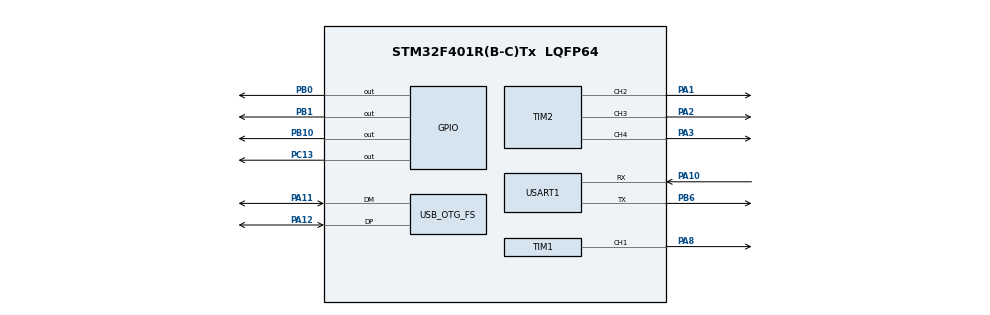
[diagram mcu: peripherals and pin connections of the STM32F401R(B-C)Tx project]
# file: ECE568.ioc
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Mcu.Family=STM32F4
Mcu.Name=STM32F401R(B-C)Tx
Mcu.Package=LQFP64
NVIC.OTG_FS_IRQn=true\:0\:0\:false\:false\:true\:false\:true\:true
NVIC.PriorityGroup=NVIC_PRIORITYGROUP_4
PA1.Signal=S_TIM2_CH2
PA10.Mode=Asynchronous
PA10.Signal=USART1_RX
PA11.Mode=Device_Only
PA11.Signal=USB_OTG_FS_DM
PA12.Mode=Device_Only
PA12.Signal=USB_OTG_FS_DP
PA2.Signal=S_TIM2_CH3
PA3.Signal=S_TIM2_CH4
PA8.Signal=S_TIM1_CH1
PB0.Signal=GPIO_Output
PB1.Signal=GPIO_Output
PB10.Signal=GPIO_Output
PB6.Mode=Asynchronous
PB6.Signal=USART1_TX
PC13-ANTI_TAMP.Signal=GPIO_Output
PH0\ -\ OSC_IN.Mode=HSE-External-Oscillator
PH0\ -\ OSC_IN.Signal=RCC_OSC_IN
PH1\ -\ OSC_OUT.Mode=HSE-External-Oscillator
PH1\ -\ OSC_OUT.Signal=RCC_OSC_OUT
ProjectManager.HeapSize=0x200
ProjectManager.StackSize=0x400
ProjectManager.TargetToolchain=STM32CubeIDE
RCC.48MHZClocksFreq_Value=48000000
RCC.AHBFreq_Value=16000000
RCC.APB1Freq_Value=16000000
RCC.APB2Freq_Value=16000000
RCC.CortexFreq_Value=16000000
RCC.HSE_VALUE=25000000
RCC.HSI_VALUE=16000000
RCC.LSE_VALUE=32768
RCC.PLLM=15
RCC.PLLN=144
RCC.PLLQ=5
RCC.SYSCLKFreq_VALUE=16000000
RCC.VCOOutputFreq_Value=240000000
SH.S_TIM1_CH1.0=TIM1_CH1,PWM Generation1 CH1
SH.S_TIM2_CH2.0=TIM2_CH2,PWM Generation2 CH2
SH.S_TIM2_CH3.0=TIM2_CH3,PWM Generation3 CH3
SH.S_TIM2_CH4.0=TIM2_CH4,PWM Generation4 CH4
TIM1.Channel-PWM\ Generation1\ CH1=TIM_CHANNEL_1
TIM2.Channel-PWM\ Generation2\ CH2=TIM_CHANNEL_2
TIM2.Channel-PWM\ Generation3\ CH3=TIM_CHANNEL_3
TIM2.Channel-PWM\ Generation4\ CH4=TIM_CHANNEL_4
USART1.VirtualMode=VM_ASYNC
USB_DEVICE.CLASS_NAME_FS=CDC
USB_DEVICE.VirtualMode=Cdc
USB_DEVICE.VirtualModeFS=Cdc_FS
USB_OTG_FS.VirtualMode=Device_Only
VP_TIM1_VS_ClockSourceINT.Mode=Internal
VP_USB_DEVICE_VS_USB_DEVICE_CDC_FS.Mode=CDC_FS
board=custom

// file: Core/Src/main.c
/* USER CODE BEGIN Header */
/**
 ******************************************************************************
 * @file           : main.c
 * @brief          : Main program body
 ******************************************************************************
 * @attention
 *
 * Copyright (c) 2026 STMicroelectronics.
 * All rights reserved.
 *
 * This software is licensed under terms that can be found in the LICENSE file
 * in the root directory of this software component.
 * If no LICENSE file comes with this software, it is provided AS-IS.
 *
 ******************************************************************************
 */
/* USER CODE END Header */
#include "main.h"
#include "usb_device.h"

/* USER CODE BEGIN Includes */
#include "signal.h"
#include "pins.h"
#include "motor.h"
#include "servo.h"
#include <stdio.h>
#include <string.h>

/* USER CODE END Includes */

TIM_HandleTypeDef htim1;
TIM_HandleTypeDef htim2;

UART_HandleTypeDef huart1;

void
SystemClock_Config (void);
static void
MX_GPIO_Init (void);
static void
MX_USART1_UART_Init (void);
static void
MX_TIM1_Init (void);
static void
MX_TIM2_Init (void);

int
main (void)
{

  /* MCU Configuration--------------------------------------------------------*/

  /* Reset of all peripherals, Initializes the Flash interface and the Systick. */
  HAL_Init ();

  /* Configure the system clock */
  SystemClock_Config ();

  /* Initialize all configured peripherals */
  MX_GPIO_Init ();
  MX_USART1_UART_Init ();
  MX_USB_DEVICE_Init ();
  MX_TIM1_Init ();
  MX_TIM2_Init ();
  /* USER CODE BEGIN 2 */
  motor_init (&htim1);
  init_servos (&htim2);

  /* USER CODE END 2 */

  /* Infinite loop */
  /* USER CODE BEGIN WHILE */
  HAL_GPIO_WritePin (GPIOC, GPIO_PIN_13, GPIO_PIN_SET);
  litter_type last_type = METAL;

  // basic signal test do: python send_signal.py --port <PORT> --duration 11 --speed 11 --bin metal
  while (1)
    {
      start_signal sig = wait_for_start ();
      if (sig.litter != last_type)
	close_all_servos ();

      motor_enable (sig.speed, 0);
      open_servo (sig.litter);
      if (sig.duration > 0)
	{
	  HAL_Delay (sig.duration);
	  motor_stop ();
	}
      else
	{
	  HAL_Delay (1000);
	}

      last_type = sig.litter;
    }
}
/* USER CODE END 3 */

void
SystemClock_Config (void)
{
  RCC_OscInitTypeDef RCC_OscInitStruct =
    { 0 };
  RCC_ClkInitTypeDef RCC_ClkInitStruct =
    { 0 };

  /** Configure the main internal regulator output voltage
   */
  __HAL_RCC_PWR_CLK_ENABLE();
  __HAL_PWR_VOLTAGESCALING_CONFIG(PWR_REGULATOR_VOLTAGE_SCALE2);

  /** Initializes the RCC Oscillators according to the specified parameters
   * in the RCC_OscInitTypeDef structure.
   */
  RCC_OscInitStruct.OscillatorType = RCC_OSCILLATORTYPE_HSI
      | RCC_OSCILLATORTYPE_HSE;
  RCC_OscInitStruct.HSEState = RCC_HSE_ON;
  RCC_OscInitStruct.HSIState = RCC_HSI_ON;
  RCC_OscInitStruct.HSICalibrationValue = RCC_HSICALIBRATION_DEFAULT;
  RCC_OscInitStruct.PLL.PLLState = RCC_PLL_ON;
  RCC_OscInitStruct.PLL.PLLSource = RCC_PLLSOURCE_HSE;
  RCC_OscInitStruct.PLL.PLLM = 15;
  RCC_OscInitStruct.PLL.PLLN = 144;
  RCC_OscInitStruct.PLL.PLLP = RCC_PLLP_DIV2;
  RCC_OscInitStruct.PLL.PLLQ = 5;
  if (HAL_RCC_OscConfig (&RCC_OscInitStruct) != HAL_OK)
    {
      Error_Handler ();
    }

  /** Initializes the CPU, AHB and APB buses clocks
   */
  RCC_ClkInitStruct.ClockType = RCC_CLOCKTYPE_HCLK | RCC_CLOCKTYPE_SYSCLK
      | RCC_CLOCKTYPE_PCLK1 | RCC_CLOCKTYPE_PCLK2;
  RCC_ClkInitStruct.SYSCLKSource = RCC_SYSCLKSOURCE_HSI;
  RCC_ClkInitStruct.AHBCLKDivider = RCC_SYSCLK_DIV1;
  RCC_ClkInitStruct.APB1CLKDivider = RCC_HCLK_DIV1;
  RCC_ClkInitStruct.APB2CLKDivider = RCC_HCLK_DIV1;

  if (HAL_RCC_ClockConfig (&RCC_ClkInitStruct, FLASH_LATENCY_0) != HAL_OK)
    {
      Error_Handler ();
    }
}

static void
MX_TIM1_Init (void)
{

  TIM_ClockConfigTypeDef sClockSourceConfig =
    { 0 };
  TIM_MasterConfigTypeDef sMasterConfig =
    { 0 };
  TIM_OC_InitTypeDef sConfigOC =
    { 0 };
  TIM_BreakDeadTimeConfigTypeDef sBreakDeadTimeConfig =
    { 0 };

  htim1.Instance = TIM1;
  htim1.Init.Prescaler = 83;
  htim1.Init.CounterMode = TIM_COUNTERMODE_UP;
  htim1.Init.Period = 49;
  htim1.Init.ClockDivision = TIM_CLOCKDIVISION_DIV1;
  htim1.Init.RepetitionCounter = 0;
  htim1.Init.AutoReloadPreload = TIM_AUTORELOAD_PRELOAD_DISABLE;
  if (HAL_TIM_Base_Init (&htim1) != HAL_OK)
    {
      Error_Handler ();
    }
  sClockSourceConfig.ClockSource = TIM_CLOCKSOURCE_INTERNAL;
  if (HAL_TIM_ConfigClockSource (&htim1, &sClockSourceConfig) != HAL_OK)
    {
      Error_Handler ();
    }
  if (HAL_TIM_PWM_Init (&htim1) != HAL_OK)
    {
      Error_Handler ();
    }
  sMasterConfig.MasterOutputTrigger = TIM_TRGO_RESET;
  sMasterConfig.MasterSlaveMode = TIM_MASTERSLAVEMODE_DISABLE;
  if (HAL_TIMEx_MasterConfigSynchronization (&htim1, &sMasterConfig) != HAL_OK)
    {
      Error_Handler ();
    }
  sConfigOC.OCMode = TIM_OCMODE_PWM1;
  sConfigOC.Pulse = 0;
  sConfigOC.OCPolarity = TIM_OCPOLARITY_HIGH;
  sConfigOC.OCNPolarity = TIM_OCNPOLARITY_HIGH;
  sConfigOC.OCFastMode = TIM_OCFAST_DISABLE;
  sConfigOC.OCIdleState = TIM_OCIDLESTATE_RESET;
  sConfigOC.OCNIdleState = TIM_OCNIDLESTATE_RESET;
  if (HAL_TIM_PWM_ConfigChannel (&htim1, &sConfigOC, TIM_CHANNEL_1) != HAL_OK)
    {
      Error_Handler ();
    }
  sBreakDeadTimeConfig.OffStateRunMode = TIM_OSSR_DISABLE;
  sBreakDeadTimeConfig.OffStateIDLEMode = TIM_OSSI_DISABLE;
  sBreakDeadTimeConfig.LockLevel = TIM_LOCKLEVEL_OFF;
  sBreakDeadTimeConfig.DeadTime = 0;
  sBreakDeadTimeConfig.BreakState = TIM_BREAK_DISABLE;
  sBreakDeadTimeConfig.BreakPolarity = TIM_BREAKPOLARITY_HIGH;
  sBreakDeadTimeConfig.AutomaticOutput = TIM_AUTOMATICOUTPUT_DISABLE;
  if (HAL_TIMEx_ConfigBreakDeadTime (&htim1, &sBreakDeadTimeConfig) != HAL_OK)
    {
      Error_Handler ();
    }
  HAL_TIM_MspPostInit (&htim1);

}

static void
MX_TIM2_Init (void)
{

  TIM_MasterConfigTypeDef sMasterConfig =
    { 0 };
  TIM_OC_InitTypeDef sConfigOC =
    { 0 };

  htim2.Instance = TIM2;
  htim2.Init.Prescaler = 15;
  htim2.Init.CounterMode = TIM_COUNTERMODE_UP;
  htim2.Init.Period = 19999;
  htim2.Init.ClockDivision = TIM_CLOCKDIVISION_DIV1;
  htim2.Init.AutoReloadPreload = TIM_AUTORELOAD_PRELOAD_DISABLE;
  if (HAL_TIM_PWM_Init (&htim2) != HAL_OK)
    {
      Error_Handler ();
    }
  sMasterConfig.MasterOutputTrigger = TIM_TRGO_RESET;
  sMasterConfig.MasterSlaveMode = TIM_MASTERSLAVEMODE_DISABLE;
  if (HAL_TIMEx_MasterConfigSynchronization (&htim2, &sMasterConfig) != HAL_OK)
    {
      Error_Handler ();
    }
  sConfigOC.OCMode = TIM_OCMODE_PWM1;
  sConfigOC.Pulse = 0;
  sConfigOC.OCPolarity = TIM_OCPOLARITY_HIGH;
  sConfigOC.OCFastMode = TIM_OCFAST_DISABLE;
  if (HAL_TIM_PWM_ConfigChannel (&htim2, &sConfigOC, TIM_CHANNEL_2) != HAL_OK)
    {
      Error_Handler ();
    }
  if (HAL_TIM_PWM_ConfigChannel (&htim2, &sConfigOC, TIM_CHANNEL_3) != HAL_OK)
    {
      Error_Handler ();
    }
  if (HAL_TIM_PWM_ConfigChannel (&htim2, &sConfigOC, TIM_CHANNEL_4) != HAL_OK)
    {
      Error_Handler ();
    }
  HAL_TIM_MspPostInit (&htim2);

}

static void
MX_USART1_UART_Init (void)
{

  huart1.Instance = USART1;
  huart1.Init.BaudRate = 115200;
  huart1.Init.WordLength = UART_WORDLENGTH_8B;
  huart1.Init.StopBits = UART_STOPBITS_1;
  huart1.Init.Parity = UART_PARITY_NONE;
  huart1.Init.Mode = UART_MODE_TX_RX;
  huart1.Init.HwFlowCtl = UART_HWCONTROL_NONE;
  huart1.Init.OverSampling = UART_OVERSAMPLING_16;
  if (HAL_UART_Init (&huart1) != HAL_OK)
    {
      Error_Handler ();
    }

}

static void
MX_GPIO_Init (void)
{
  GPIO_InitTypeDef GPIO_InitStruct =
    { 0 };

  /* GPIO Ports Clock Enable */
  __HAL_RCC_GPIOC_CLK_ENABLE();
  __HAL_RCC_GPIOH_CLK_ENABLE();
  __HAL_RCC_GPIOA_CLK_ENABLE();
  __HAL_RCC_GPIOB_CLK_ENABLE();

  /*Configure GPIO pin Output Level */
  HAL_GPIO_WritePin (GPIOC, GPIO_PIN_13, GPIO_PIN_RESET);

  /*Configure GPIO pin Output Level */
  HAL_GPIO_WritePin (GPIOB, GPIO_PIN_0 | GPIO_PIN_1 | GPIO_PIN_10,
		     GPIO_PIN_RESET);

  /*Configure GPIO pin : PC13 */
  GPIO_InitStruct.Pin = GPIO_PIN_13;
  GPIO_InitStruct.Mode = GPIO_MODE_OUTPUT_PP;
  GPIO_InitStruct.Pull = GPIO_NOPULL;
  GPIO_InitStruct.Speed = GPIO_SPEED_FREQ_LOW;
  HAL_GPIO_Init (GPIOC, &GPIO_InitStruct);

  /*Configure GPIO pins : PB0 PB1 PB10 */
  GPIO_InitStruct.Pin = GPIO_PIN_0 | GPIO_PIN_1 | GPIO_PIN_10;
  GPIO_InitStruct.Mode = GPIO_MODE_OUTPUT_PP;
  GPIO_InitStruct.Pull = GPIO_NOPULL;
  GPIO_InitStruct.Speed = GPIO_SPEED_FREQ_LOW;
  HAL_GPIO_Init (GPIOB, &GPIO_InitStruct);

}

void
Error_Handler (void)
{
  /* USER CODE BEGIN Error_Handler_Debug */
  /* User can add his own implementation to report the HAL error return state */
  __disable_irq ();
  while (1)
    {
    }
  /* USER CODE END Error_Handler_Debug */
}
